# earlgrey register map
Vendor: lowRISC OpenTitan; File version: snapshot-20191101-1-518-g9293d546-dirty
CPU: RISCV 0, little endian, MPU, no FPU, 0 interrupt priority bits
Registers are 32-bit, read-write, reset 0x0 unless marked. A register's access mark holds for its fields unless they carry their own. Offsets are from the block's base; [hi:lo] are bit positions; {n}, {i} and the like mark numbered series; 'fields as' and 'values as' point back to an identical list.

## spi_device
Base 0x40020000
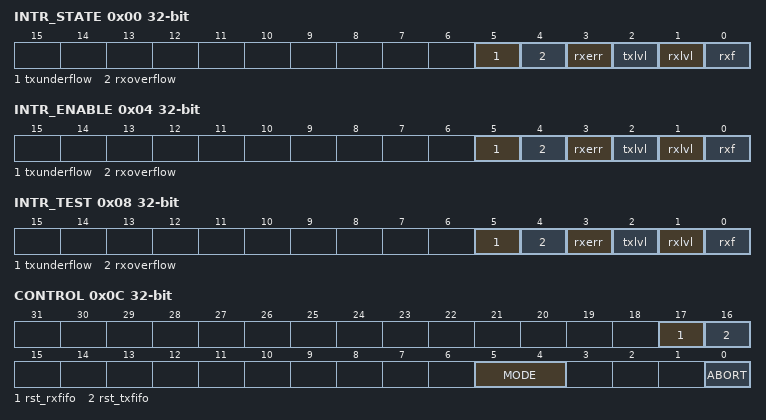
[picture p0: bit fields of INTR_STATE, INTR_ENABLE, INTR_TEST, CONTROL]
0x00 INTR_STATE — Interrupt State Register
  [5] txunderflow write-1-clears — TX Async FIFO underflow
  [4] rxoverflow write-1-clears — RX Async FIFO overflow
  [3] rxerr write-1-clears — MOSI in FwMode has error
  [2] txlvl write-1-clears — TX SRAM FIFO is under the level
  [1] rxlvl write-1-clears — RX SRAM FIFO is above the level
  [0] rxf write-1-clears — RX SRAM FIFO Full
0x04 INTR_ENABLE — Interrupt Enable Register
  [5] txunderflow — Enable interrupt when !!INTR_STATE.txunderflow is set
  [4] rxoverflow — Enable interrupt when !!INTR_STATE.rxoverflow is set
  [3] rxerr — Enable interrupt when !!INTR_STATE.rxerr is set
  [2] txlvl — Enable interrupt when !!INTR_STATE.txlvl is set
  [1] rxlvl — Enable interrupt when !!INTR_STATE.rxlvl is set
  [0] rxf — Enable interrupt when !!INTR_STATE.rxf is set
0x08 INTR_TEST wo — Interrupt Test Register
  [5] txunderflow — Write 1 to force !!INTR_STATE.txunderflow to 1
  [4] rxoverflow — Write 1 to force !!INTR_STATE.rxoverflow to 1
  [3] rxerr — Write 1 to force !!INTR_STATE.rxerr to 1
  [2] txlvl — Write 1 to force !!INTR_STATE.txlvl to 1
  [1] rxlvl — Write 1 to force !!INTR_STATE.rxlvl to 1
  [0] rxf — Write 1 to force !!INTR_STATE.rxf to 1
0x0C CONTROL
  [17] rst_rxfifo — Reset Async RX_FIFO. This only resets asynchronous fifo. If firmware wants to reset SRAM FIFO, it should write 0 into read pointer and write pointer. _Note_: This value should be controlled only when SPI interface is in Idle state as this reset signal doesn't have reset synchronizer.
  [16] rst_txfifo — Reset Async TX_FIFO. This only resets asynchronous fifo. If firmware wants to reset SRAM FIFO, it should write 0 into read/write pointers. _Note_: This value should be controlled only when SPI interface is in Idle state as this reset signal doesn't have reset synchronizer.
  [5:4] MODE — SPI Device operation mode. Currently only FwMode is supported.
  [0] ABORT — Abort pending jobs. If TX_FIFO (async) is full, this command can let TXF Control logic back to Idle state
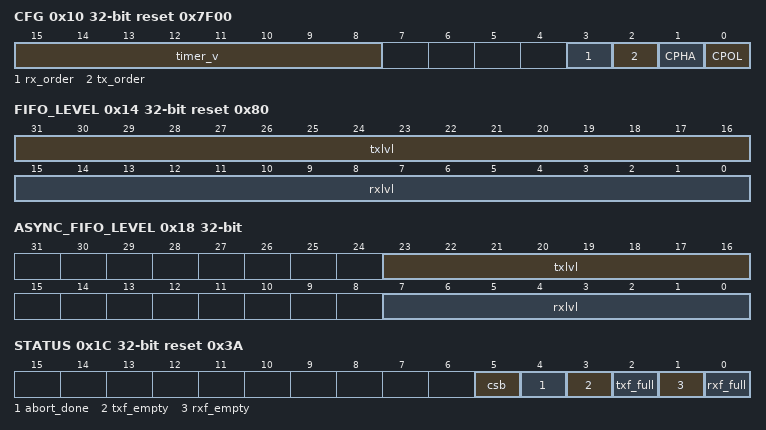
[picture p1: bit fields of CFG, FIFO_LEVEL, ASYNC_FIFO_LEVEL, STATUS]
0x10 CFG reset 0x7F00 — Configuration Register
  [15:8] timer_v — number of clocks for RXF to wait. To reduce traffic to SRAM, RXF control module waits given clock cycle if it doesn't fill SRAM data width even if Async RX FIFO is empty.
  [3] rx_order — RX bit order on MOSI. Module stores bitstream from MSB to LSB if value is 0.
  [2] tx_order — TX bit order on MISO. 0 for MSB to LSB, 1 for LSB to MSB
  [1] CPHA — Data phase. 0 for negative edge change, 1 for positive edge change
  [0] CPOL — Clock polarity. 0 for normal SPI, 1 for negative edge latch
0x14 FIFO_LEVEL reset 0x80 — RX/ TX FIFO levels.
  [31:16] txlvl — TX FIFO level. If TX SRAM FIFO level drops below this value, it triggers interrupt.
  [15:0] rxlvl — RX FIFO level. If RX SRAM FIFO level exceeds this value, it triggers interrupt.
0x18 ASYNC_FIFO_LEVEL ro — RX/ TX Async FIFO levels between main clk and spi clock
  [23:16] txlvl — TX Async FIFO level. This value shows the number of available entry in TX Async FIFO. If the software writes message into SRAM FIFO and update FIFO write pointer but no clock from the host is given, the data stuck at this async fifo waiting host toggles SCK. This value represents the number of bytes.
  [7:0] rxlvl — RX Async FIFO level. This value shows the number of available entry in RX Async FIFO.
0x1C STATUS ro reset 0x3A — SPI Device status register
  [5] csb — Direct input of CSb signal
  [4] abort_done — Abort process is completed
  [3] txf_empty — TX FIFO empty
  [2] txf_full — TX FIFO full
  [1] rxf_empty — RX FIFO empty
  [0] rxf_full — RX FIFO full
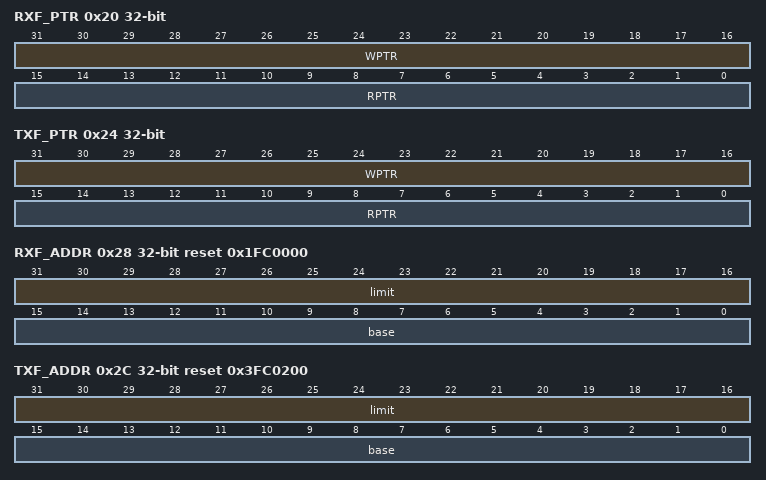
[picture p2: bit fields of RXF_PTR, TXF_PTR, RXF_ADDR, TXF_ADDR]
0x20 RXF_PTR — Receiver FIFO (SRAM) pointers
  [31:16] WPTR ro — Write pointer. Bit x is phase bit.
  [15:0] RPTR — Read pointer. bit x is for phase bit. check circular fifo description
0x24 TXF_PTR — Transmitter FIFO (SRAM) pointers
  [31:16] WPTR — Write pointer. Bit x is phase bit.
  [15:0] RPTR ro — Read pointer. bit x is for phase bit. check circular fifo description
0x28 RXF_ADDR reset 0x1FC0000 — Receiver FIFO (SRAM) Addresses
  [31:16] limit — Limit offset in bytes in the SRAM. Lower 2 bits are ignored.
  [15:0] base — Base offset in bytes in the SRAM. Lower 2 bits are ignored.
0x2C TXF_ADDR reset 0x3FC0200 — Transmitter FIFO (SRAM) Addresses
  fields as RXF_ADDR
{0x800+4i} buffer{i} (i=0..511) reset not defined — SPI internal 2kB buffer. This buffer is shared by RX and TX circular buffer together.
